# PIC32MZ2048EFM144 register map
Vendor: Microchip
Registers are 32-bit, read-write, reset 0x0 unless marked. A register's access mark holds for its fields unless they carry their own. Addresses are absolute, and some are shared; only a register's first bit layout is shown; [hi:lo] are bit positions.

## TMR4
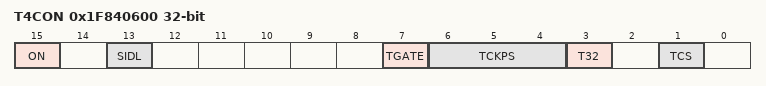
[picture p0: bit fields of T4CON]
0x1F840600 T4CON
  [15] ON, [13] SIDL, [7] TGATE, [6:4] TCKPS, [3] T32, [1] TCS
0x1F840610 TMR4
0x1F840620 PR4 reset 0xFFFF

## TMR5
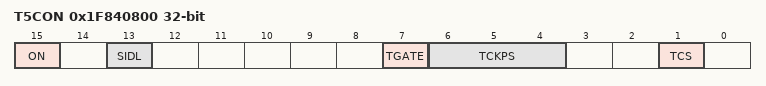
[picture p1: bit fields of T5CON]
0x1F840800 T5CON
  [15] ON, [13] SIDL, [7] TGATE, [6:4] TCKPS, [1] TCS
0x1F840810 TMR5
0x1F840820 PR5 reset 0xFFFF

## TMR6
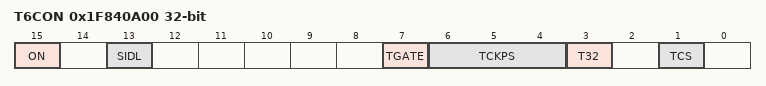
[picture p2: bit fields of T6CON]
0x1F840A00 T6CON
  [15] ON, [13] SIDL, [7] TGATE, [6:4] TCKPS, [3] T32, [1] TCS
0x1F840A10 TMR6
0x1F840A20 PR6 reset 0xFFFF

## TMR7
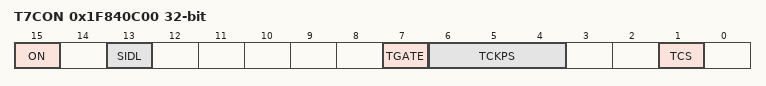
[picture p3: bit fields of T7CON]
0x1F840C00 T7CON
  [15] ON, [13] SIDL, [7] TGATE, [6:4] TCKPS, [1] TCS
0x1F840C10 TMR7
0x1F840C20 PR7 reset 0xFFFF

## TMR8
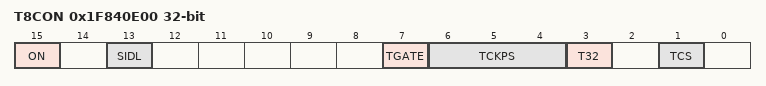
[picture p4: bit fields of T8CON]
0x1F840E00 T8CON
  [15] ON, [13] SIDL, [7] TGATE, [6:4] TCKPS, [3] T32, [1] TCS
0x1F840E10 TMR8
0x1F840E20 PR8 reset 0xFFFF

## TMR9
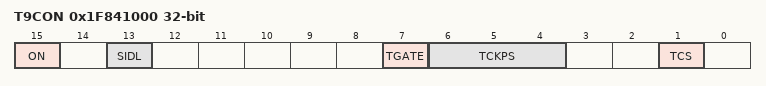
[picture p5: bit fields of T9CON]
0x1F841000 T9CON
  [15] ON, [13] SIDL, [7] TGATE, [6:4] TCKPS, [1] TCS
0x1F841010 TMR9
0x1F841020 PR9 reset 0xFFFF

## ICAP1
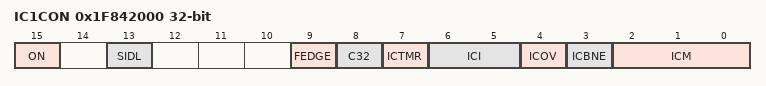
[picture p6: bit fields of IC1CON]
0x1F842000 IC1CON
  [15] ON, [13] SIDL, [9] FEDGE, [8] C32, [7] ICTMR, [6:5] ICI, [4] ICOV ro, [3] ICBNE ro, [2:0] ICM
0x1F842010 IC1BUF ro reset not defined — (power-on value xxxxxxxxxxxxxxxxxxxxxxxxxxxxxxxx)

## ICAP2
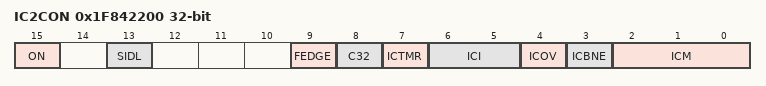
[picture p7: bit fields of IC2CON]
0x1F842200 IC2CON
  [15] ON, [13] SIDL, [9] FEDGE, [8] C32, [7] ICTMR, [6:5] ICI, [4] ICOV ro, [3] ICBNE ro, [2:0] ICM
0x1F842210 IC2BUF ro reset not defined — (power-on value xxxxxxxxxxxxxxxxxxxxxxxxxxxxxxxx)

## ICAP3
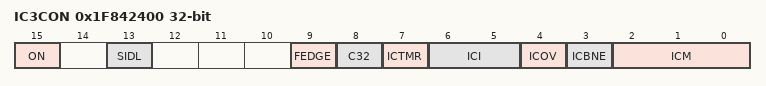
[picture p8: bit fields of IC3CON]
0x1F842400 IC3CON
  [15] ON, [13] SIDL, [9] FEDGE, [8] C32, [7] ICTMR, [6:5] ICI, [4] ICOV ro, [3] ICBNE ro, [2:0] ICM
0x1F842410 IC3BUF ro reset not defined — (power-on value xxxxxxxxxxxxxxxxxxxxxxxxxxxxxxxx)

## ICAP4
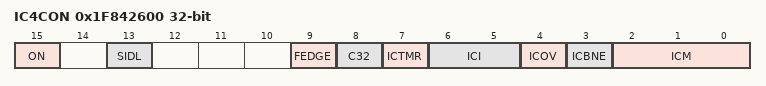
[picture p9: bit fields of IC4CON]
0x1F842600 IC4CON
  [15] ON, [13] SIDL, [9] FEDGE, [8] C32, [7] ICTMR, [6:5] ICI, [4] ICOV ro, [3] ICBNE ro, [2:0] ICM
0x1F842610 IC4BUF ro reset not defined — (power-on value xxxxxxxxxxxxxxxxxxxxxxxxxxxxxxxx)

## ICAP5
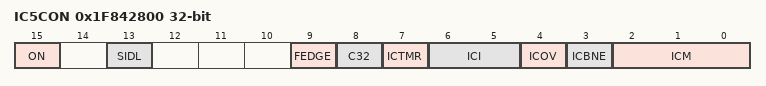
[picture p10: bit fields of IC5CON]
0x1F842800 IC5CON
  [15] ON, [13] SIDL, [9] FEDGE, [8] C32, [7] ICTMR, [6:5] ICI, [4] ICOV ro, [3] ICBNE ro, [2:0] ICM
0x1F842810 IC5BUF ro reset not defined — (power-on value xxxxxxxxxxxxxxxxxxxxxxxxxxxxxxxx)

## ICAP6
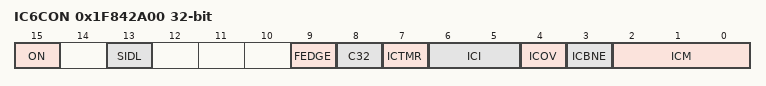
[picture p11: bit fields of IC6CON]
0x1F842A00 IC6CON
  [15] ON, [13] SIDL, [9] FEDGE, [8] C32, [7] ICTMR, [6:5] ICI, [4] ICOV ro, [3] ICBNE ro, [2:0] ICM
0x1F842A10 IC6BUF ro reset not defined — (power-on value xxxxxxxxxxxxxxxxxxxxxxxxxxxxxxxx)

## ICAP7
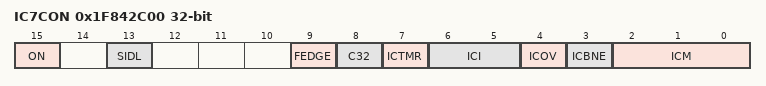
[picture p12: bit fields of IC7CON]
0x1F842C00 IC7CON
  [15] ON, [13] SIDL, [9] FEDGE, [8] C32, [7] ICTMR, [6:5] ICI, [4] ICOV ro, [3] ICBNE ro, [2:0] ICM
0x1F842C10 IC7BUF ro reset not defined — (power-on value xxxxxxxxxxxxxxxxxxxxxxxxxxxxxxxx)

## ICAP8
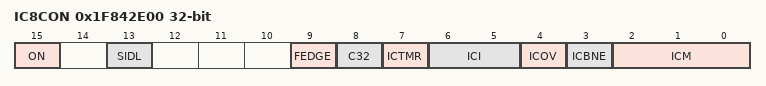
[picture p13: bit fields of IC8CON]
0x1F842E00 IC8CON
  [15] ON, [13] SIDL, [9] FEDGE, [8] C32, [7] ICTMR, [6:5] ICI, [4] ICOV ro, [3] ICBNE ro, [2:0] ICM
0x1F842E10 IC8BUF ro reset not defined — (power-on value xxxxxxxxxxxxxxxxxxxxxxxxxxxxxxxx)

## ICAP9
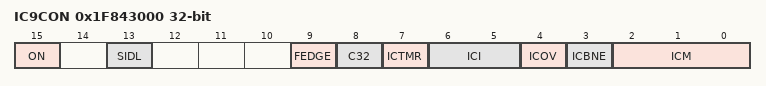
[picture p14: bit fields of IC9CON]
0x1F843000 IC9CON
  [15] ON, [13] SIDL, [9] FEDGE, [8] C32, [7] ICTMR, [6:5] ICI, [4] ICOV ro, [3] ICBNE ro, [2:0] ICM
0x1F843010 IC9BUF ro reset not defined — (power-on value xxxxxxxxxxxxxxxxxxxxxxxxxxxxxxxx)

## OCMP1
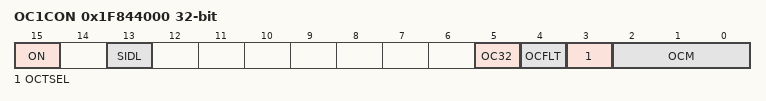
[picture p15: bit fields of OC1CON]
0x1F844000 OC1CON
  [15] ON, [13] SIDL, [5] OC32, [4] OCFLT ro, [3] OCTSEL, [2:0] OCM
0x1F844010 OC1R reset not defined — (power-on value xxxxxxxxxxxxxxxxxxxxxxxxxxxxxxxx)
0x1F844020 OC1RS reset not defined — (power-on value xxxxxxxxxxxxxxxxxxxxxxxxxxxxxxxx)

## OCMP2
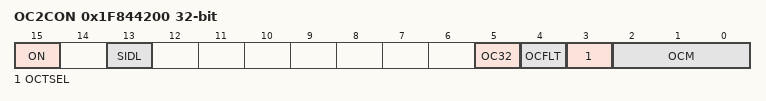
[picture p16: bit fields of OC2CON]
0x1F844200 OC2CON
  [15] ON, [13] SIDL, [5] OC32, [4] OCFLT ro, [3] OCTSEL, [2:0] OCM
0x1F844210 OC2R reset not defined — (power-on value xxxxxxxxxxxxxxxxxxxxxxxxxxxxxxxx)
0x1F844220 OC2RS reset not defined — (power-on value xxxxxxxxxxxxxxxxxxxxxxxxxxxxxxxx)
